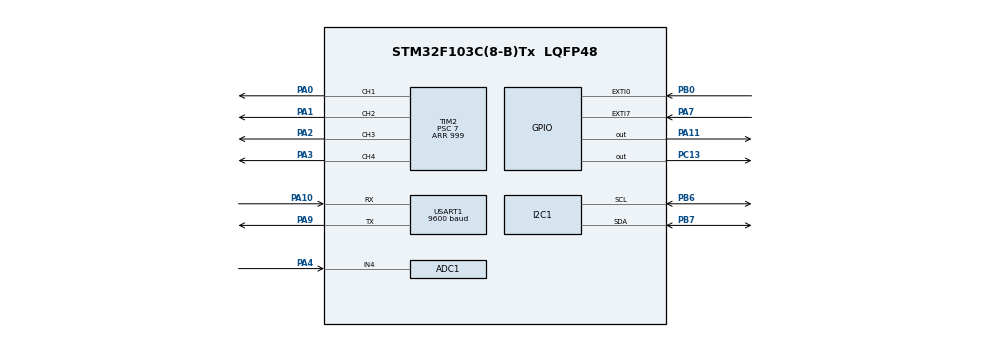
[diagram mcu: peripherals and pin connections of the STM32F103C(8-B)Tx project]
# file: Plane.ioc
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ADC1.Channel-1\#ChannelRegularConversion=ADC_CHANNEL_4
ADC1.NbrOfConversionFlag=1
ADC1.Rank-1\#ChannelRegularConversion=1
ADC1.SamplingTime-1\#ChannelRegularConversion=ADC_SAMPLETIME_1CYCLE_5
ADC1.master=1
Dma.I2C1_RX.0.Direction=DMA_PERIPH_TO_MEMORY
Dma.I2C1_RX.0.Instance=DMA1_Channel7
Dma.I2C1_RX.0.MemDataAlignment=DMA_MDATAALIGN_BYTE
Dma.I2C1_RX.0.MemInc=DMA_MINC_ENABLE
Dma.I2C1_RX.0.Mode=DMA_NORMAL
Dma.I2C1_RX.0.PeriphDataAlignment=DMA_PDATAALIGN_BYTE
Dma.I2C1_RX.0.PeriphInc=DMA_PINC_DISABLE
Dma.I2C1_RX.0.Priority=DMA_PRIORITY_LOW
Dma.I2C1_TX.1.Direction=DMA_MEMORY_TO_PERIPH
Dma.I2C1_TX.1.Instance=DMA1_Channel6
Dma.I2C1_TX.1.MemDataAlignment=DMA_MDATAALIGN_BYTE
Dma.I2C1_TX.1.MemInc=DMA_MINC_ENABLE
Dma.I2C1_TX.1.Mode=DMA_NORMAL
Dma.I2C1_TX.1.PeriphDataAlignment=DMA_PDATAALIGN_BYTE
Dma.I2C1_TX.1.PeriphInc=DMA_PINC_DISABLE
Dma.I2C1_TX.1.Priority=DMA_PRIORITY_LOW
Dma.Request0=I2C1_RX
Dma.Request1=I2C1_TX
FREERTOS.Queues01=BlueQueue01,16,Fly_ModeTDF,0,Dynamic,NULL,NULL;MPUQueue02,24,MPU6050_HandleDataTDF,0,Dynamic,NULL,NULL
FREERTOS.Tasks01=defaultTask,24,128,StartDefaultTask,Default,NULL,Dynamic,NULL,NULL;BlueTask01,40,128,BlueStartTask01,Default,NULL,Dynamic,NULL,NULL;MPUTask02,40,128,MPUStartTask02,Default,NULL,Dynamic,NULL,NULL;PidTask03,32,256,PidStartTask03,Default,NULL,Dynamic,NULL,NULL
FREERTOS.configTOTAL_HEAP_SIZE=4096
Mcu.Family=STM32F1
Mcu.Name=STM32F103C(8-B)Tx
Mcu.Package=LQFP48
NVIC.DMA1_Channel6_IRQn=true\:5\:0\:false\:false\:true\:true\:false\:true\:true
NVIC.DMA1_Channel7_IRQn=true\:5\:0\:false\:false\:true\:true\:false\:true\:true
NVIC.PriorityGroup=NVIC_PRIORITYGROUP_4
NVIC.USART1_IRQn=true\:5\:0\:false\:false\:true\:true\:true\:true\:true
PA0-WKUP.Signal=S_TIM2_CH1_ETR
PA1.Signal=S_TIM2_CH2
PA10.Mode=Asynchronous
PA10.Signal=USART1_RX
PA11.Signal=GPIO_Output
PA13.Mode=Serial_Wire
PA13.Signal=SYS_JTMS-SWDIO
PA14.Mode=Serial_Wire
PA14.Signal=SYS_JTCK-SWCLK
PA2.Signal=S_TIM2_CH3
PA3.Signal=S_TIM2_CH4
PA4.Signal=ADCx_IN4
PA7.Signal=GPXTI7
PA9.Mode=Asynchronous
PA9.Signal=USART1_TX
PB0.Signal=GPXTI0
PB6.Mode=I2C
PB6.Signal=I2C1_SCL
PB7.Mode=I2C
PB7.Signal=I2C1_SDA
PC13-TAMPER-RTC.Signal=GPIO_Output
PD0-OSC_IN.Mode=HSE-External-Oscillator
PD0-OSC_IN.Signal=RCC_OSC_IN
PD1-OSC_OUT.Mode=HSE-External-Oscillator
PD1-OSC_OUT.Signal=RCC_OSC_OUT
ProjectManager.HeapSize=0x200
ProjectManager.StackSize=0x400
ProjectManager.TargetToolchain=MDK-ARM V5.32
RCC.APB1Freq_Value=8000000
RCC.APB2Freq_Value=8000000
RCC.PLLSourceVirtual=RCC_PLLSOURCE_HSE
RCC.USBFreq_Value=16000000
SH.ADCx_IN4.0=ADC1_IN4,IN4
SH.S_TIM2_CH1_ETR.0=TIM2_CH1,PWM Generation1 CH1
SH.S_TIM2_CH2.0=TIM2_CH2,PWM Generation2 CH2
SH.S_TIM2_CH3.0=TIM2_CH3,PWM Generation3 CH3
SH.S_TIM2_CH4.0=TIM2_CH4,PWM Generation4 CH4
TIM2.Channel-PWM\ Generation1\ CH1=TIM_CHANNEL_1
TIM2.Channel-PWM\ Generation2\ CH2=TIM_CHANNEL_2
TIM2.Channel-PWM\ Generation3\ CH3=TIM_CHANNEL_3
TIM2.Channel-PWM\ Generation4\ CH4=TIM_CHANNEL_4
TIM2.Period=999
TIM2.Prescaler=7
USART1.BaudRate=9600
USART1.VirtualMode=VM_ASYNC
VP_FREERTOS_VS_CMSIS_V2.Mode=CMSIS_V2
board=custom

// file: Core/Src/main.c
/* USER CODE BEGIN Header */
/**
  ******************************************************************************
  * @file           : main.c
  * @brief          : Main program body
  ******************************************************************************
  * @attention
  *
  * Copyright (c) 2026 STMicroelectronics.
  * All rights reserved.
  *
  * This software is licensed under terms that can be found in the LICENSE file
  * in the root directory of this software component.
  * If no LICENSE file comes with this software, it is provided AS-IS.
  *
  ******************************************************************************
  */
/* USER CODE END Header */
#include "main.h"
#include "cmsis_os.h"
#include "adc.h"
#include "dma.h"
#include "i2c.h"
#include "tim.h"
#include "usart.h"
#include "gpio.h"

void SystemClock_Config(void);
void MX_FREERTOS_Init(void);

int main(void)
{

  /* MCU Configuration--------------------------------------------------------*/

  /* Reset of all peripherals, Initializes the Flash interface and the Systick. */
  HAL_Init();

  /* Configure the system clock */
  SystemClock_Config();

  /* Initialize all configured peripherals */
  MX_GPIO_Init();
  MX_DMA_Init();
  MX_I2C1_Init();
  MX_TIM2_Init();
  MX_USART1_UART_Init();
  MX_ADC1_Init();

  /* Init scheduler */
  osKernelInitialize();  /* Call init function for freertos objects (in cmsis_os2.c) */
  MX_FREERTOS_Init();

  /* Start scheduler */
  osKernelStart();

  /* We should never get here as control is now taken by the scheduler */

  /* Infinite loop */
  while (1)
  {

  }
}

void SystemClock_Config(void)
{
  RCC_OscInitTypeDef RCC_OscInitStruct = {0};
  RCC_ClkInitTypeDef RCC_ClkInitStruct = {0};
  RCC_PeriphCLKInitTypeDef PeriphClkInit = {0};

  /** Initializes the RCC Oscillators according to the specified parameters
  * in the RCC_OscInitTypeDef structure.
  */
  RCC_OscInitStruct.OscillatorType = RCC_OSCILLATORTYPE_HSI;
  RCC_OscInitStruct.HSIState = RCC_HSI_ON;
  RCC_OscInitStruct.HSICalibrationValue = RCC_HSICALIBRATION_DEFAULT;
  RCC_OscInitStruct.PLL.PLLState = RCC_PLL_NONE;
  if (HAL_RCC_OscConfig(&RCC_OscInitStruct) != HAL_OK)
  {
    Error_Handler();
  }

  /** Initializes the CPU, AHB and APB buses clocks
  */
  RCC_ClkInitStruct.ClockType = RCC_CLOCKTYPE_HCLK|RCC_CLOCKTYPE_SYSCLK
                              |RCC_CLOCKTYPE_PCLK1|RCC_CLOCKTYPE_PCLK2;
  RCC_ClkInitStruct.SYSCLKSource = RCC_SYSCLKSOURCE_HSI;
  RCC_ClkInitStruct.AHBCLKDivider = RCC_SYSCLK_DIV1;
  RCC_ClkInitStruct.APB1CLKDivider = RCC_HCLK_DIV1;
  RCC_ClkInitStruct.APB2CLKDivider = RCC_HCLK_DIV1;

  if (HAL_RCC_ClockConfig(&RCC_ClkInitStruct, FLASH_LATENCY_0) != HAL_OK)
  {
    Error_Handler();
  }
  PeriphClkInit.PeriphClockSelection = RCC_PERIPHCLK_ADC;
  PeriphClkInit.AdcClockSelection = RCC_ADCPCLK2_DIV2;
  if (HAL_RCCEx_PeriphCLKConfig(&PeriphClkInit) != HAL_OK)
  {
    Error_Handler();
  }
}

void Error_Handler(void)
{
  __disable_irq();
  while (1)
  {
  }
}

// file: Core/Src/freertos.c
/* USER CODE BEGIN Header */
/**
  ******************************************************************************
  * File Name          : freertos.c
  * Description        : Code for freertos applications
  ******************************************************************************
  * @attention
  *
  * Copyright (c) 2026 STMicroelectronics.
  * All rights reserved.
  *
  * This software is licensed under terms that can be found in the LICENSE file
  * in the root directory of this software component.
  * If no LICENSE file comes with this software, it is provided AS-IS.
  *
  ******************************************************************************
  */
/* USER CODE END Header */

#include "FreeRTOS.h"
#include "task.h"
#include "main.h"
#include "cmsis_os.h"

/* USER CODE BEGIN Includes */
#include "TASKMY.h"
/* USER CODE END Includes */

/* Definitions for defaultTask */
osThreadId_t defaultTaskHandle;
const osThreadAttr_t defaultTask_attributes = {
  .name = "defaultTask",
  .stack_size = 128 * 4,
  .priority = (osPriority_t) osPriorityNormal,
};
/* Definitions for BlueTask01 */
osThreadId_t BlueTask01Handle;
const osThreadAttr_t BlueTask01_attributes = {
  .name = "BlueTask01",
  .stack_size = 128 * 4,
  .priority = (osPriority_t) osPriorityHigh,
};
/* Definitions for MPUTask02 */
osThreadId_t MPUTask02Handle;
const osThreadAttr_t MPUTask02_attributes = {
  .name = "MPUTask02",
  .stack_size = 128 * 4,
  .priority = (osPriority_t) osPriorityHigh,
};
/* Definitions for PidTask03 */
osThreadId_t PidTask03Handle;
const osThreadAttr_t PidTask03_attributes = {
  .name = "PidTask03",
  .stack_size = 256 * 4,
  .priority = (osPriority_t) osPriorityAboveNormal,
};
/* Definitions for BlueQueue01 */
osMessageQueueId_t BlueQueue01Handle;
const osMessageQueueAttr_t BlueQueue01_attributes = {
  .name = "BlueQueue01"
};
/* Definitions for MPUQueue02 */
osMessageQueueId_t MPUQueue02Handle;
const osMessageQueueAttr_t MPUQueue02_attributes = {
  .name = "MPUQueue02"
};

void StartDefaultTask(void *argument);
void BlueStartTask01(void *argument);
void MPUStartTask02(void *argument);
void PidStartTask03(void *argument);

void MX_FREERTOS_Init(void); /* (MISRA C 2004 rule 8.1) */

void MX_FREERTOS_Init(void) {

  /* Create the queue(s) */
  /* creation of BlueQueue01 */
  BlueQueue01Handle = osMessageQueueNew (16, sizeof(Fly_ModeTDF), &BlueQueue01_attributes);

  /* creation of MPUQueue02 */
  MPUQueue02Handle = osMessageQueueNew (24, sizeof(MPU6050_HandleDataTDF), &MPUQueue02_attributes);

  /* Create the thread(s) */
  /* creation of defaultTask */
  defaultTaskHandle = osThreadNew(StartDefaultTask, NULL, &defaultTask_attributes);

  /* creation of BlueTask01 */
  BlueTask01Handle = osThreadNew(BlueStartTask01, NULL, &BlueTask01_attributes);

  /* creation of MPUTask02 */
  MPUTask02Handle = osThreadNew(MPUStartTask02, NULL, &MPUTask02_attributes);

  /* creation of PidTask03 */
  PidTask03Handle = osThreadNew(PidStartTask03, NULL, &PidTask03_attributes);

}

void StartDefaultTask(void *argument)
{
  /* USER CODE BEGIN StartDefaultTask */
  /* Infinite loop */

  for(;;)
  {
    LedTask();
    osDelay(10);

  }
  /* USER CODE END StartDefaultTask */
}

void BlueStartTask01(void *argument)
{
  /* USER CODE BEGIN BlueStartTask01 */
  /* Infinite loop */

  v_Bluetooth_Init();

  for(;;)
  {
	vBlueTask();
	/*osDelay(10)~osDelay(80)与[1,10]的映射  作用是控制蓝牙发送数据的快慢，见Variable.h*/
    osDelay((int)((70 * BLUE_SEND_TIME)/9 + 0.5));
  }
  /* USER CODE END BlueStartTask01 */
}

void MPUStartTask02(void *argument)
{
  /* USER CODE BEGIN MPUStartTask02 */
  /* Infinite loop */
  vMPU6050_Init();
  for(;;)
  {
    v_MPU6050Task();
    osDelay(10);
  }
  /* USER CODE END MPUStartTask02 */
}

void PidStartTask03(void *argument)
{
  /* USER CODE BEGIN PidStartTask03 */
  /* Infinite loop */
	Motor_Init();
  for(;;)
  {
	v_PidTask();
    osDelay(10);
  }
  /* USER CODE END PidStartTask03 */
}
